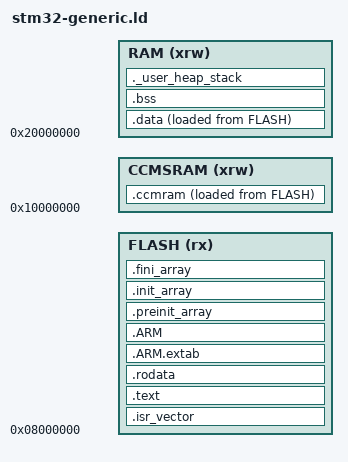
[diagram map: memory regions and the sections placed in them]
/*
 * RULOS Note: This was originally one of the linker scripts from the STMCube F1
 * distribution, specifically STM32F103XB_FLASH.ld. The STM32F1 distribution
 * had linker files for each chip family, which was nice. However, the STM32F0
 * and STM32F3 files had no gcc linker files. But:
 *
 *  1) In the STM32F1 distribution, all the linker scripts were identical
 *     except for the size of flash and RAM.
 *
 *  2) The libopencm project uses a single (parameterized) linker script
 *     for all cortex Ms.
 *
 * We're going to assume that within the STM32 line (F0, F1, F3), the location
 * of flash and location of RAM are always the same; only the lengths change.
 *
 * So the RULOS ARM makefiles specify the amount of FLASH, RAM, and CCM RAM
 * for every chip and run a script that sed's this template. CCM SRAM
 * (Core Coupled Memory) is zero-wait-state RAM on STM32F3/G4, connected to
 * both the I-bus and D-bus. Functions placed in .ccmram are copied from flash
 * at boot by rulos_hal_init(). For chips without CCM, CCMRAMK is 0 and the
 * section is empty.
 */

/* Entry Point */
ENTRY(Reset_Handler)

/* Specify the memory areas *//* Generate a link error if heap and stack don't fit into RAM */
_Min_Heap_Size = 0x0;      /* required amount of heap  */
_Min_Stack_Size = 0x0; /* required amount of stack */

MEMORY
{
FLASH (rx)      : ORIGIN = 0x08000000, LENGTH = %RULOS_FLASHK%K
RAM (xrw)       : ORIGIN = 0x20000000, LENGTH = %RULOS_RAMK%K
CCMSRAM (xrw)   : ORIGIN = 0x10000000, LENGTH = %RULOS_CCMRAMK%K
}

/* Highest address of the user mode stack */
_estack = ORIGIN(RAM) + LENGTH(RAM);

/* Define output sections */
SECTIONS
{
  /* The startup code goes first into FLASH */
  .isr_vector :
  {
    . = ALIGN(4);
    KEEP(*(.isr_vector)) /* Startup code */
    . = ALIGN(4);
  } >FLASH

  /* The program code and other data goes into FLASH */
  .text :
  {
    . = ALIGN(4);
    *(.text)           /* .text sections (code) */
    *(.text*)          /* .text* sections (code) */
    *(.glue_7)         /* glue arm to thumb code */
    *(.glue_7t)        /* glue thumb to arm code */
    *(.eh_frame)

    KEEP (*(.init))
    KEEP (*(.fini))

    . = ALIGN(4);
    _etext = .;        /* define a global symbols at end of code */
  } >FLASH

  /* Constant data goes into FLASH */
  .rodata :
  {
    . = ALIGN(4);
    *(.rodata)         /* .rodata sections (constants, strings, etc.) */
    *(.rodata*)        /* .rodata* sections (constants, strings, etc.) */
    . = ALIGN(4);
  } >FLASH

  .ARM.extab   : { *(.ARM.extab* .gnu.linkonce.armextab.*) } >FLASH
  .ARM : {
    __exidx_start = .;
    *(.ARM.exidx*)
    __exidx_end = .;
  } >FLASH

  .preinit_array     :
  {
    PROVIDE_HIDDEN (__preinit_array_start = .);
    KEEP (*(.preinit_array*))
    PROVIDE_HIDDEN (__preinit_array_end = .);
  } >FLASH
  .init_array :
  {
    PROVIDE_HIDDEN (__init_array_start = .);
    KEEP (*(SORT(.init_array.*)))
    KEEP (*(.init_array*))
    PROVIDE_HIDDEN (__init_array_end = .);
  } >FLASH
  .fini_array :
  {
    PROVIDE_HIDDEN (__fini_array_start = .);
    KEEP (*(SORT(.fini_array.*)))
    KEEP (*(.fini_array*))
    PROVIDE_HIDDEN (__fini_array_end = .);
  } >FLASH

  /* used by the startup to initialize data */
  _sidata = LOADADDR(.data);

  /* Initialized data sections goes into RAM, load LMA copy after code */
  .data : 
  {
    . = ALIGN(4);
    _sdata = .;        /* create a global symbol at data start */
    *(.data)           /* .data sections */
    *(.data*)          /* .data* sections */

    . = ALIGN(4);
    _edata = .;        /* define a global symbol at data end */
  } >RAM AT> FLASH

  /* CCM SRAM section: code/data copied from flash to CCM RAM at boot */
  _siccmram = LOADADDR(.ccmram);
  .ccmram :
  {
    . = ALIGN(4);
    _sccmram = .;
    *(.ccmram)
    *(.ccmram*)
    . = ALIGN(4);
    _eccmram = .;
  } >CCMSRAM AT> FLASH

  /* Uninitialized data section */
  . = ALIGN(4);
  .bss :
  {
    /* This is used by the startup in order to initialize the .bss secion */
    _sbss = .;         /* define a global symbol at bss start */
    __bss_start__ = _sbss;
    *(.bss)
    *(.bss*)
    *(COMMON)

    . = ALIGN(4);
    _ebss = .;         /* define a global symbol at bss end */
    __bss_end__ = _ebss;
  } >RAM

  /* User_heap_stack section, used to check that there is enough RAM left */
  ._user_heap_stack :
  {
    . = ALIGN(8);
    PROVIDE ( end = . );
    PROVIDE ( _end = . );
    . = . + _Min_Heap_Size;
    . = . + _Min_Stack_Size;
    . = ALIGN(8);
  } >RAM

  /* Remove information from the standard libraries */
  /DISCARD/ :
  {
    libc.a ( * )
    libm.a ( * )
    libgcc.a ( * )
  }

  .ARM.attributes 0 : { *(.ARM.attributes) }
}
